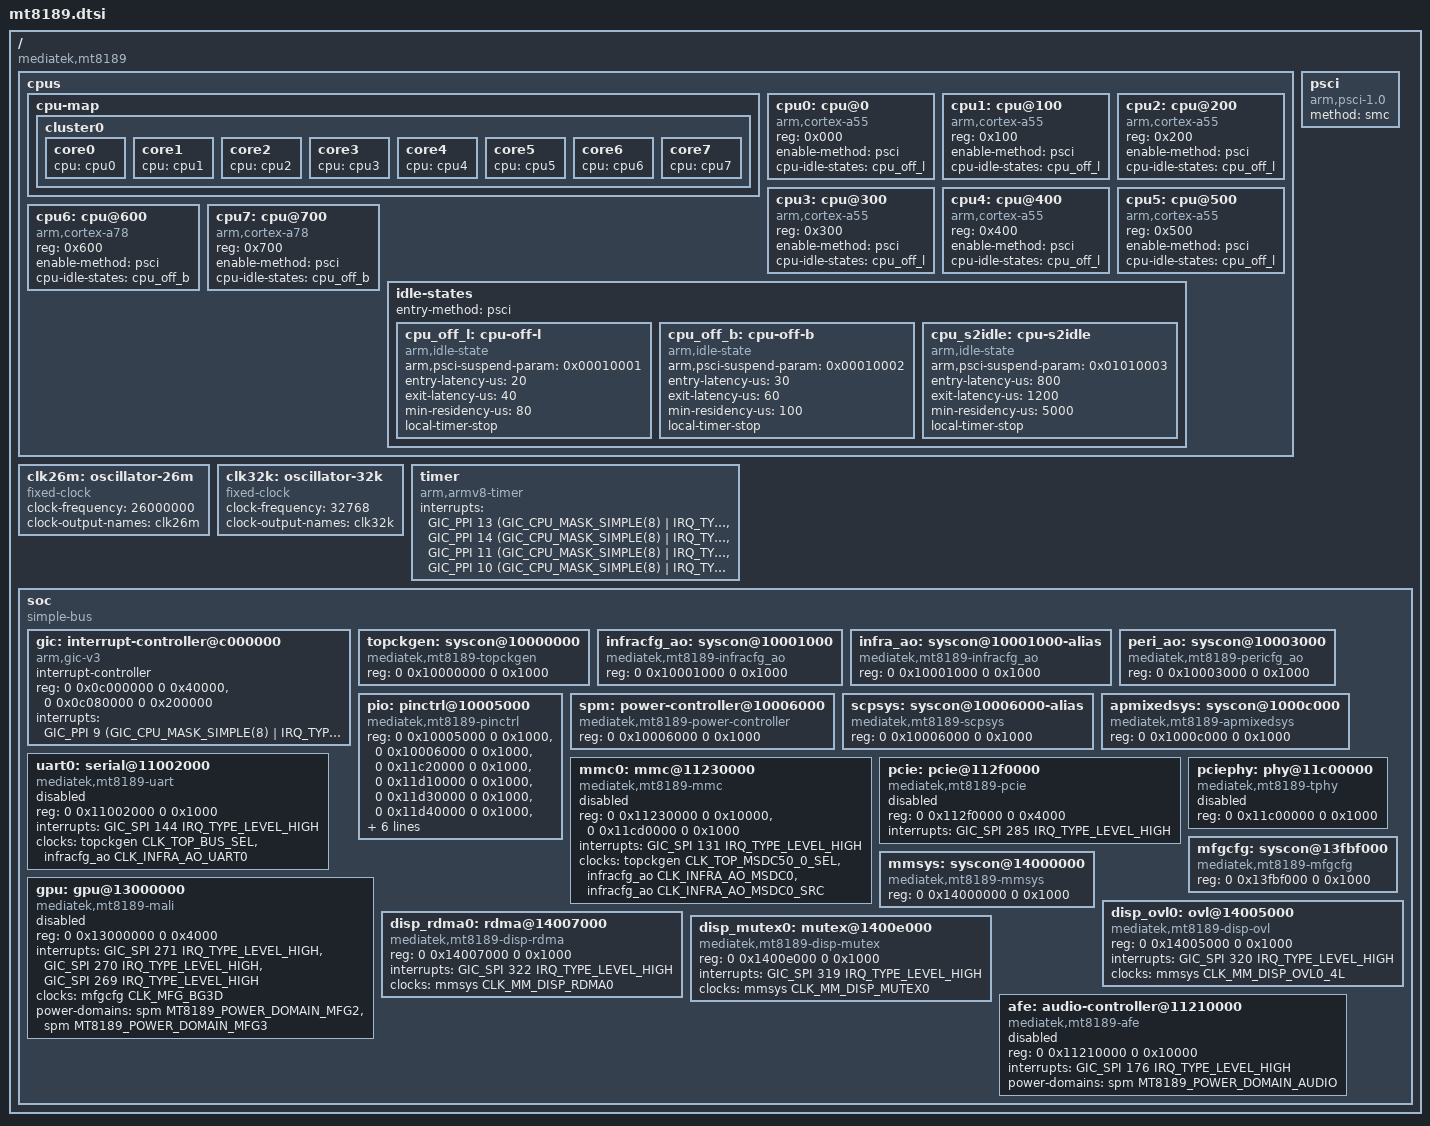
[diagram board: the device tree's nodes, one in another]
// SPDX-License-Identifier: (GPL-2.0 OR MIT)
/*
 * Base Device Tree Source for MediaTek MT8189 (Kompanio 540) SoC.
 * 8 cores: 2x Cortex-A78 (up to 2.6GHz) + 6x Cortex-A55 (2.0GHz).
 * Architecture: ARM64 / aarch64.
 */

#include <dt-bindings/interrupt-controller/arm-gic.h>
#include <dt-bindings/interrupt-controller/irq.h>
#include <dt-bindings/clock/mediatek,mt8189-clk.h>
#include <dt-bindings/reset/mediatek,mt8189-resets.h>
#include "include/dt-bindings/power/mediatek,mt8189-power.h"

/ {
	compatible = "mediatek,mt8189";
	#address-cells = <2>;
	#size-cells = <2>;

	cpus {
		#address-cells = <1>;
		#size-cells = <0>;

		cpu-map {
			cluster0 {
				core0 { cpu = <&cpu0>; };
				core1 { cpu = <&cpu1>; };
				core2 { cpu = <&cpu2>; };
				core3 { cpu = <&cpu3>; };
				core4 { cpu = <&cpu4>; };
				core5 { cpu = <&cpu5>; };
				core6 { cpu = <&cpu6>; };
				core7 { cpu = <&cpu7>; };
			};
		};

		cpu0: cpu@0 {
			device_type = "cpu";
			compatible = "arm,cortex-a55";
			reg = <0x000>;
			enable-method = "psci";
			cpu-idle-states = <&cpu_off_l>;
			#cooling-cells = <2>;
		};

		cpu1: cpu@100 {
			device_type = "cpu";
			compatible = "arm,cortex-a55";
			reg = <0x100>;
			enable-method = "psci";
			cpu-idle-states = <&cpu_off_l>;
			#cooling-cells = <2>;
		};

		cpu2: cpu@200 {
			device_type = "cpu";
			compatible = "arm,cortex-a55";
			reg = <0x200>;
			enable-method = "psci";
			cpu-idle-states = <&cpu_off_l>;
			#cooling-cells = <2>;
		};

		cpu3: cpu@300 {
			device_type = "cpu";
			compatible = "arm,cortex-a55";
			reg = <0x300>;
			enable-method = "psci";
			cpu-idle-states = <&cpu_off_l>;
			#cooling-cells = <2>;
		};

		cpu4: cpu@400 {
			device_type = "cpu";
			compatible = "arm,cortex-a55";
			reg = <0x400>;
			enable-method = "psci";
			cpu-idle-states = <&cpu_off_l>;
			#cooling-cells = <2>;
		};

		cpu5: cpu@500 {
			device_type = "cpu";
			compatible = "arm,cortex-a55";
			reg = <0x500>;
			enable-method = "psci";
			cpu-idle-states = <&cpu_off_l>;
			#cooling-cells = <2>;
		};

		cpu6: cpu@600 {
			device_type = "cpu";
			compatible = "arm,cortex-a78";
			reg = <0x600>;
			enable-method = "psci";
			cpu-idle-states = <&cpu_off_b>;
			#cooling-cells = <2>;
		};

		cpu7: cpu@700 {
			device_type = "cpu";
			compatible = "arm,cortex-a78";
			reg = <0x700>;
			enable-method = "psci";
			cpu-idle-states = <&cpu_off_b>;
			#cooling-cells = <2>;
		};

		idle-states {
			entry-method = "psci";

			cpu_off_l: cpu-off-l {
				compatible = "arm,idle-state";
				arm,psci-suspend-param = <0x00010001>;
				entry-latency-us = <20>;
				exit-latency-us = <40>;
				min-residency-us = <80>;
				local-timer-stop;
			};

			cpu_off_b: cpu-off-b {
				compatible = "arm,idle-state";
				arm,psci-suspend-param = <0x00010002>;
				entry-latency-us = <30>;
				exit-latency-us = <60>;
				min-residency-us = <100>;
				local-timer-stop;
			};

			cpu_s2idle: cpu-s2idle {
				compatible = "arm,idle-state";
				arm,psci-suspend-param = <0x01010003>;
				entry-latency-us = <800>;
				exit-latency-us = <1200>;
				min-residency-us = <5000>;
				local-timer-stop;
			};
		};
	};

	psci {
		compatible = "arm,psci-1.0", "arm,psci-0.2";
		method = "smc";
	};

	clk26m: oscillator-26m {
		compatible = "fixed-clock";
		#clock-cells = <0>;
		clock-frequency = <26000000>;
		clock-output-names = "clk26m";
	};

	clk32k: oscillator-32k {
		compatible = "fixed-clock";
		#clock-cells = <0>;
		clock-frequency = <32768>;
		clock-output-names = "clk32k";
	};

	timer {
		compatible = "arm,armv8-timer";
		interrupts = <GIC_PPI 13 (GIC_CPU_MASK_SIMPLE(8) | IRQ_TYPE_LEVEL_LOW)>,
			     <GIC_PPI 14 (GIC_CPU_MASK_SIMPLE(8) | IRQ_TYPE_LEVEL_LOW)>,
			     <GIC_PPI 11 (GIC_CPU_MASK_SIMPLE(8) | IRQ_TYPE_LEVEL_LOW)>,
			     <GIC_PPI 10 (GIC_CPU_MASK_SIMPLE(8) | IRQ_TYPE_LEVEL_LOW)>;
	};

	soc {
		#address-cells = <2>;
		#size-cells = <2>;
		compatible = "simple-bus";
		ranges;

		gic: interrupt-controller@c000000 {
			compatible = "arm,gic-v3";
			#interrupt-cells = <3>;
			#address-cells = <2>;
			#size-cells = <2>;
			ranges;
			interrupt-controller;
			reg = <0 0x0c000000 0 0x40000>,
			      <0 0x0c080000 0 0x200000>;
			interrupts = <GIC_PPI 9 (GIC_CPU_MASK_SIMPLE(8) | IRQ_TYPE_LEVEL_HIGH)>;
		};

		topckgen: syscon@10000000 {
			compatible = "mediatek,mt8189-topckgen", "syscon";
			reg = <0 0x10000000 0 0x1000>;
			#clock-cells = <1>;
		};

		infracfg_ao: syscon@10001000 {
			compatible = "mediatek,mt8189-infracfg_ao", "syscon";
			reg = <0 0x10001000 0 0x1000>;
			#clock-cells = <1>;
			#reset-cells = <1>;
		};

		infra_ao: syscon@10001000-alias {
			compatible = "mediatek,mt8189-infracfg_ao", "syscon";
			reg = <0 0x10001000 0 0x1000>;
			#clock-cells = <1>;
		};

		peri_ao: syscon@10003000 {
			compatible = "mediatek,mt8189-pericfg_ao", "syscon";
			reg = <0 0x10003000 0 0x1000>;
			#clock-cells = <1>;
		};

		pio: pinctrl@10005000 {
			compatible = "mediatek,mt8189-pinctrl";
			reg = <0 0x10005000 0 0x1000>,
			      <0 0x10006000 0 0x1000>,
			      <0 0x11c20000 0 0x1000>,
			      <0 0x11d10000 0 0x1000>,
			      <0 0x11d30000 0 0x1000>,
			      <0 0x11d40000 0 0x1000>,
			      <0 0x11e20000 0 0x1000>,
			      <0 0x11e30000 0 0x1000>,
			      <0 0x11eb0000 0 0x1000>,
			      <0 0x11f40000 0 0x1000>;
			reg-names = "iocfg0", "iocfg_bm", "iocfg_lt", "iocfg_lm",
				    "iocfg_lb", "iocfg_bl", "iocfg_rb", "iocfg_rt",
				    "iocfg_rm", "iocfg_tl";
			gpio-controller;
			#gpio-cells = <2>;
			interrupt-controller;
			#interrupt-cells = <2>;
			interrupts = <GIC_SPI 225 IRQ_TYPE_LEVEL_HIGH>;
		};

		spm: power-controller@10006000 {
			compatible = "mediatek,mt8189-power-controller";
			reg = <0 0x10006000 0 0x1000>;
			#power-domain-cells = <1>;
		};

		scpsys: syscon@10006000-alias {
			compatible = "mediatek,mt8189-scpsys", "syscon";
			reg = <0 0x10006000 0 0x1000>;
			#power-domain-cells = <1>;
		};

		apmixedsys: syscon@1000c000 {
			compatible = "mediatek,mt8189-apmixedsys", "syscon";
			reg = <0 0x1000c000 0 0x1000>;
			#clock-cells = <1>;
		};

		uart0: serial@11002000 {
			compatible = "mediatek,mt8189-uart", "mediatek,mt6577-uart";
			reg = <0 0x11002000 0 0x1000>;
			interrupts = <GIC_SPI 144 IRQ_TYPE_LEVEL_HIGH>;
			clocks = <&topckgen CLK_TOP_BUS_SEL>, <&infracfg_ao CLK_INFRA_AO_UART0>;
			clock-names = "baud", "bus";
			status = "disabled";
		};

		/* 128 GB eMMC 5.1 (MSDC0) */
		mmc0: mmc@11230000 {
			compatible = "mediatek,mt8189-mmc", "mediatek,mt8183-mmc";
			reg = <0 0x11230000 0 0x10000>,
			      <0 0x11cd0000 0 0x1000>;
			interrupts = <GIC_SPI 131 IRQ_TYPE_LEVEL_HIGH>;
			clocks = <&topckgen CLK_TOP_MSDC50_0_SEL>,
				 <&infracfg_ao CLK_INFRA_AO_MSDC0>,
				 <&infracfg_ao CLK_INFRA_AO_MSDC0_SRC>;
			clock-names = "source", "hclk", "source_cg";
			status = "disabled";
		};

		/* MediaTek PCIe Gen3 Controller (Wi-Fi 7 MT7925 / MT7922) */
		pcie: pcie@112f0000 {
			compatible = "mediatek,mt8189-pcie", "mediatek,mt8192-pcie";
			device_type = "pci";
			reg = <0 0x112f0000 0 0x4000>;
			reg-names = "pcie-mac";
			#address-cells = <3>;
			#size-cells = <2>;
			ranges = <0x82000000 0 0x20000000 0 0x20000000 0 0x10000000>;
			interrupts = <GIC_SPI 285 IRQ_TYPE_LEVEL_HIGH>;
			status = "disabled";
		};

		pciephy: phy@11c00000 {
			compatible = "mediatek,mt8189-tphy", "mediatek,generic-tphy-v2";
			reg = <0 0x11c00000 0 0x1000>;
			#phy-cells = <1>;
			status = "disabled";
		};

		/* ARM Mali-G57 MC2 GPU */
		mfgcfg: syscon@13fbf000 {
			compatible = "mediatek,mt8189-mfgcfg", "syscon";
			reg = <0 0x13fbf000 0 0x1000>;
			#clock-cells = <1>;
		};

		gpu: gpu@13000000 {
			compatible = "mediatek,mt8189-mali", "mediatek,mt8370-mali", "arm,mali-valhall-jm";
			reg = <0 0x13000000 0 0x4000>;
			interrupts = <GIC_SPI 271 IRQ_TYPE_LEVEL_HIGH>,
				     <GIC_SPI 270 IRQ_TYPE_LEVEL_HIGH>,
				     <GIC_SPI 269 IRQ_TYPE_LEVEL_HIGH>;
			interrupt-names = "job", "mmu", "gpu";
			clocks = <&mfgcfg CLK_MFG_BG3D>;
			power-domains = <&spm MT8189_POWER_DOMAIN_MFG2>, <&spm MT8189_POWER_DOMAIN_MFG3>;
			power-domain-names = "core0", "core1";
			status = "disabled";
		};

		/* MediaTek Display Subsystem (MMSYS) */
		mmsys: syscon@14000000 {
			compatible = "mediatek,mt8189-mmsys", "syscon";
			reg = <0 0x14000000 0 0x1000>;
			#clock-cells = <1>;
		};

		disp_ovl0: ovl@14005000 {
			compatible = "mediatek,mt8189-disp-ovl", "mediatek,mt8186-disp-ovl";
			reg = <0 0x14005000 0 0x1000>;
			interrupts = <GIC_SPI 320 IRQ_TYPE_LEVEL_HIGH>;
			clocks = <&mmsys CLK_MM_DISP_OVL0_4L>;
		};

		disp_rdma0: rdma@14007000 {
			compatible = "mediatek,mt8189-disp-rdma", "mediatek,mt8186-disp-rdma";
			reg = <0 0x14007000 0 0x1000>;
			interrupts = <GIC_SPI 322 IRQ_TYPE_LEVEL_HIGH>;
			clocks = <&mmsys CLK_MM_DISP_RDMA0>;
		};

		disp_mutex0: mutex@1400e000 {
			compatible = "mediatek,mt8189-disp-mutex", "mediatek,mt8186-disp-mutex";
			reg = <0 0x1400e000 0 0x1000>;
			interrupts = <GIC_SPI 319 IRQ_TYPE_LEVEL_HIGH>;
			clocks = <&mmsys CLK_MM_DISP_MUTEX0>;
		};

		/* Audio Frontend (AFE) */
		afe: audio-controller@11210000 {
			compatible = "mediatek,mt8189-afe";
			reg = <0 0x11210000 0 0x10000>;
			interrupts = <GIC_SPI 176 IRQ_TYPE_LEVEL_HIGH>;
			power-domains = <&spm MT8189_POWER_DOMAIN_AUDIO>;
			status = "disabled";
		};
	};
};

